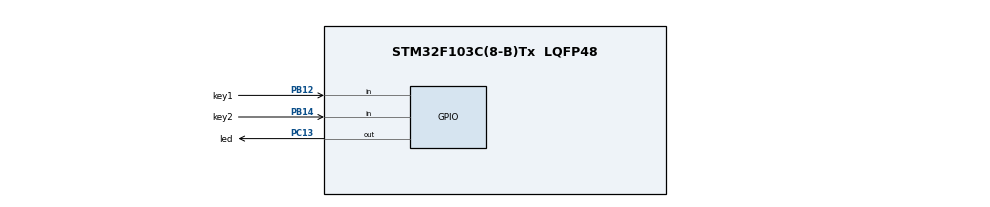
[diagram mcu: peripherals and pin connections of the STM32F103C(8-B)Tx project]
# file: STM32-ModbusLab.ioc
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Mcu.Family=STM32F1
Mcu.Name=STM32F103C(8-B)Tx
Mcu.Package=LQFP48
NVIC.PriorityGroup=NVIC_PRIORITYGROUP_4
PB12.GPIO_Label=key1
PB12.GPIO_PuPd=GPIO_PULLUP
PB12.Signal=GPIO_Input
PB14.GPIO_Label=key2
PB14.GPIO_PuPd=GPIO_PULLUP
PB14.Signal=GPIO_Input
PC13-TAMPER-RTC.GPIO_Label=led
PC13-TAMPER-RTC.GPIO_PuPd=GPIO_PULLUP
PC13-TAMPER-RTC.Signal=GPIO_Output
PD0-OSC_IN.Mode=HSE-External-Oscillator
PD0-OSC_IN.Signal=RCC_OSC_IN
PD1-OSC_OUT.Mode=HSE-External-Oscillator
PD1-OSC_OUT.Signal=RCC_OSC_OUT
ProjectManager.HeapSize=0x200
ProjectManager.StackSize=0x400
ProjectManager.TargetToolchain=CMake
RCC.AHBFreq_Value=72000000
RCC.APB1CLKDivider=RCC_HCLK_DIV2
RCC.APB1Freq_Value=36000000
RCC.APB1TimFreq_Value=72000000
RCC.APB2Freq_Value=72000000
RCC.APB2TimFreq_Value=72000000
RCC.HCLKFreq_Value=72000000
RCC.PLLMUL=RCC_PLL_MUL9
RCC.PLLSourceVirtual=RCC_PLLSOURCE_HSE
RCC.SYSCLKFreq_VALUE=72000000
RCC.SYSCLKSource=RCC_SYSCLKSOURCE_PLLCLK
RCC.USBFreq_Value=72000000
VP_SYS_VS_ND.Mode=No_Debug
board=custom

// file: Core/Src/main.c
/* USER CODE BEGIN Header */
/**
  ******************************************************************************
  * @file           : main.c
  * @brief          : Main program body
  ******************************************************************************
  * @attention
  *
  * Copyright (c) 2026 STMicroelectronics.
  * All rights reserved.
  *
  * This software is licensed under terms that can be found in the LICENSE file
  * in the root directory of this software component.
  * If no LICENSE file comes with this software, it is provided AS-IS.
  *
  ******************************************************************************
  */
/* USER CODE END Header */
#include "main.h"
#include "gpio.h"

/* USER CODE BEGIN Includes */
#include "bsp_includes.h"
#include "modbus_device.h"
/* USER CODE END Includes */

void SystemClock_Config(void);

int main(void)
{

  /* MCU Configuration--------------------------------------------------------*/

  /* Reset of all peripherals, Initializes the Flash interface and the Systick. */
  LL_APB2_GRP1_EnableClock(LL_APB2_GRP1_PERIPH_AFIO);
  LL_APB1_GRP1_EnableClock(LL_APB1_GRP1_PERIPH_PWR);

  /* System interrupt init*/
  NVIC_SetPriorityGrouping(NVIC_PRIORITYGROUP_4);

  /* SysTick_IRQn interrupt configuration */
  NVIC_SetPriority(SysTick_IRQn, NVIC_EncodePriority(NVIC_GetPriorityGrouping(),15, 0));

  /* CubeMX 默认的 DisableRemap_SWJ 会同时关闭 JTAG-DP 与 SW-DP，
     程序一旦运行 SWD 调试/下载口即断开。PB10/PB11 不属于 SWJ 引脚，
     改为 NOJTAG 保留 SW-DP，二者无冲突。 */
  /** NOJTAG: JTAG-DP Disabled and SW-DP Enabled
  */
  LL_GPIO_AF_Remap_SWJ_NOJTAG();

  /* Configure the system clock */
  SystemClock_Config();

  /* Initialize all configured peripherals */
  MX_GPIO_Init();
  /* USER CODE BEGIN 2 */

  /* 1. 统一时间基准：SysTick 1ms 心跳 + DWT 微秒计时 */
  Timebase_Init();

  /* 2. 按键（裸机 MultiButton），驱动内部完成 GPIO 初始化 */
  KEY_Init();

  /* 3. OLED 初始化：总线与引脚配置在 bsp_i2c.c 中统一完成 */
  Delay_ms(100);            /* 上电稳定后再发 OLED 初始化命令 */
  OLED_Init(&g_oled);
  OLED_Clear(&g_oled);

  /* 4. AT24xx 初始化：与 OLED 共用同一条 IIC 总线，检测结果存于 g_at24xx_online */
  (void)AT24XX_PortInit();

  /* 5. 测试模块：上电自测（OLED + EEPROM 读写）后进入交互测试主界面 */
#if BSP_MODBUS_ENABLE
  OLED_ShowString(&g_oled, 0, 0, "MODBUS RTU", OLED_8X16);
  OLED_ShowString(&g_oled, 0, 16, "115200 8E1", OLED_8X16);
  OLED_Update(&g_oled);
  MbApp_Init();
#else
  AppTest_Init();
#endif

  /* USER CODE END 2 */

  /* Infinite loop */
  while (1)
  {

    /* USER CODE BEGIN 3 */
#if BSP_MODBUS_ENABLE
    MbApp_Poll();
#else
    AppTest_Task();   /* 测试任务：按键扫描、事件处理、运行指示（内部按毫秒计时，非阻塞） */
#endif
  }
  /* USER CODE END 3 */
}

void SystemClock_Config(void)
{
  LL_FLASH_SetLatency(LL_FLASH_LATENCY_2);
  while(LL_FLASH_GetLatency()!= LL_FLASH_LATENCY_2)
  {
  }
  LL_RCC_HSE_Enable();

   /* Wait till HSE is ready */
  while(LL_RCC_HSE_IsReady() != 1)
  {

  }
  LL_RCC_PLL_ConfigDomain_SYS(LL_RCC_PLLSOURCE_HSE_DIV_1, LL_RCC_PLL_MUL_9);
  LL_RCC_PLL_Enable();

   /* Wait till PLL is ready */
  while(LL_RCC_PLL_IsReady() != 1)
  {

  }
  LL_RCC_SetAHBPrescaler(LL_RCC_SYSCLK_DIV_1);
  LL_RCC_SetAPB1Prescaler(LL_RCC_APB1_DIV_2);
  LL_RCC_SetAPB2Prescaler(LL_RCC_APB2_DIV_1);
  LL_RCC_SetSysClkSource(LL_RCC_SYS_CLKSOURCE_PLL);

   /* Wait till System clock is ready */
  while(LL_RCC_GetSysClkSource() != LL_RCC_SYS_CLKSOURCE_STATUS_PLL)
  {

  }
  LL_Init1msTick(72000000);
  LL_SetSystemCoreClock(72000000);
}

void Error_Handler(void)
{
  __disable_irq();
  while (1)
  {
  }
}
